# NUC505_v1 register map
File version: 1.0
Registers are 32-bit, read-write, reset 0x0 unless marked. A register's access mark holds for its fields unless they carry their own. Offsets are from the block's base; [hi:lo] are bit positions; {n}, {i} and the like mark numbered series; 'fields as' and 'values as' point back to an identical list.

## USBH — USBH Register Map
Base 0x4000B000
0x00 HCREVISION ro reset 0x110 — Host Controller Revision Register
  [7:0] REV — Revision. Indicates the Open HCI Specification revision number implemented by the Hardware. Host Controller supports 1.1 specification.
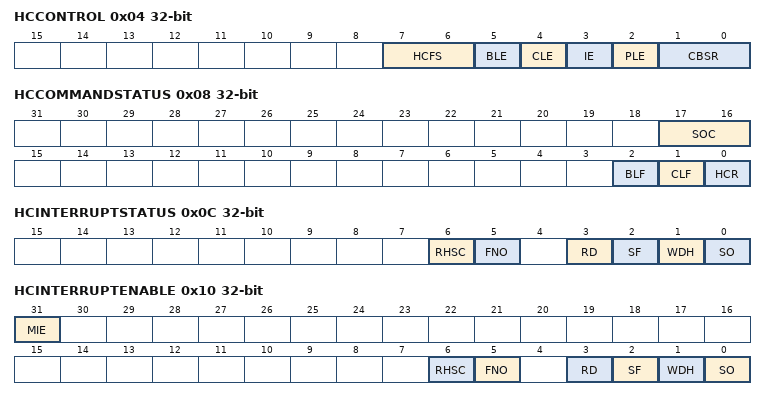
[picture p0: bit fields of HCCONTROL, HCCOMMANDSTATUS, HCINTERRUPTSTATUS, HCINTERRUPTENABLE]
0x04 HCCONTROL — Host Controller Control Register
  [7:6] HCFS — Host Controller Functional State. This field sets the Host Controller state. The Controller may force a state change from USBSUSPEND to USBRESUME after detecting resume signaling from a downstream port. States are:
    0=USBRESET; 1=USBRESUME; 2=USBOPERATIONAL; 3=USBSUSPEND
  [5] BLE — Bulk List Enable Bit
    0=Processing of the Bulk list after next SOF (Start-Of-Frame) Disabled; 1=Processing of the Bulk list in the next frame Enabled
  [4] CLE — Control List Enable Bit
    0=Processing of the Control list after next SOF (Start-Of-Frame) Disabled; 1=Processing of the Control list in the next frame Enabled
  [3] IE — Isochronous Enable Bit. Both ISOEn and PLE (HcControl[2]) high enables Host Controller to process the Isochronous list. Either ISOEn or PLE (HcControl[2]) is low disables Host Controller to process the Isochronous list.
    0=Processing of the Isochronous list after next SOF (Start-Of-Frame) Disabled; 1=Processing of the Isochronous list in the next frame Enabled, if the PLE (HcControl[2]) is high, too
  [2] PLE — Periodic List Enable Bit. When set, this bit enables processing of the Periodic (interrupt and isochronous) list. The Host Controller checks this bit prior to attempting any periodic transfers in a frame. To enable the processing of the Isochronous list, user has to set both PLE and IE (HcControl[3]) high.
    0=Processing of the Periodic (Interrupt and Isochronous) list after next SOF (Start-Of-Frame) Disabled; 1=Processing of the Periodic (Interrupt and Isochronous) list in the next frame Enabled
  [1:0] CBSR — Control Bulk Service Ratio. This specifies the service ratio between Control and Bulk EDs. Before processing any of the non-periodic lists, HC must compare the ratio specified with its internal count on how many nonempty Control EDs have been processed, in determining whether to continue serving another Control ED or switching to Bulk EDs. The internal count will be retained when crossing the frame boundary. In case of reset, HCD is responsible for restoring this. Value.
    {v}=Number of Control EDs over Bulk EDs served is {v+1}:1 (v=0..3)
0x08 HCCOMMANDSTATUS — Host Controller Command Status Register
  [17:16] SOC — Scheduling Overrun Count. These bits are incremented on each scheduling overrun error. It is initialized to 00b and wraps around at 11b. This will be incremented when a scheduling overrun is detected even if SO (HcInterruptStatus[0]) has already been set.
  [2] BLF — Bulk List Filled. Set high to indicate there is an active TD on the Bulk list. This bit may be set by either software or the Host Controller and cleared by the Host Controller each time it begins processing the head of the Bulk list.
    0=No active TD found or Host Controller begins to process the head of the Bulk list; 1=An active TD added or found on the Bulk list
  [1] CLF — Control List Filled. Set high to indicate there is an active TD on the Control List. It may be set by either software or the Host Controller and cleared by the Host Controller each time it begins processing the head of the Control List.
    0=No active TD found or Host Controller begins to process the head of the Control list; 1=An active TD added or found on the Control list
  [0] HCR — Host Controller Reset. This bit is set to initiate the software reset of Host Controller. This bit is cleared by the Host Controller, upon completed of the reset operation. This bit, when set, didn't reset the Root Hub and no subsequent reset signaling be asserted to its downstream ports.
    0=Host Controller is not in software reset state; 1=Host Controller is in software reset state
0x0C HCINTERRUPTSTATUS — Host Controller Interrupt Status Register
  [6] RHSC — Root Hub Status Change. This bit is set when the content of HcRhStatus or the content of HcRhPortStatus1 register has changed.
    0=The content of HcRhStatus and the content of HcRhPortStatus1 register didn't change; 1=The content of HcRhStatus or the content of HcRhPortStatus1 register has changed
  [5] FNO — Frame Number Overflow. This bit is set when bit 15 of Frame Number changes from 1 to 0 or from 0 to 1.
    0=The bit 15 of Frame Number didn't change; 1=The bit 15 of Frame Number changes from 1 to 0 or from 0 to 1
  [3] RD — Resume Detected. Set when Host Controller detects resume signaling on a downstream port.
    0=No resume signaling detected on a downstream port; 1=Resume signaling detected on a downstream port
  [2] SF — Start of Frame. Set when the Frame Management functional block signals a 'Start of Frame' event. Host Control generates a SOF token at the same time.
    0=.Not the start of a frame; 1=.Indicate the start of a frame and Host Controller generates a SOF token
  [1] WDH — Write Back Done Head. Set after the Host Controller has written HcDoneHead to HccaDoneHead. Further updates of the HccaDoneHead will not occur until this bit has been cleared.
    0=.Host Controller didn't update HccaDoneHead; 1=.Host Controller has written HcDoneHead to HccaDoneHead
  [0] SO — Scheduling Overrun. Set when the List Processor determines a Schedule Overrun has occurred.
    0=Schedule Overrun didn't occur; 1=Schedule Overrun has occurred
0x10 HCINTERRUPTENABLE — Host Controller Interrupt Enable Control Register
  [31] MIE — Master Interrupt Enable Bit. This bit is a global interrupt enable. A write of '1' allows interrupts to be enabled via the specific enable bits listed above. Write Operation:
    0=No effect. Interrupt generation due to RHSC (HcInterruptStatus[6]), FNO (HcInterruptStatus[5]), RD (HcInterruptStatus[3]), SF (HcInterruptStatus[2]), WDH (HcInterruptStatus[1]) or SO (HcInterruptStatus[0]) Disabled even if the corresponding bit in HcInterruptEnable is high; 1=Interrupt generation due to RHSC (HcInterruptStatus[6]), FNO (HcInterruptStatus[5]), RD (HcInterruptStatus[3]), SF (HcInterruptStatus[2]), WDH (HcInterruptStatus[1]) or SO (HcInterruptStatus[0]) Enabled if the corresponding bit in HcInterruptEnable is high
  [6] RHSC — Root Hub Status Change Interrupt Enable Bit. Write Operation:
    0=No effect. Interrupt generation due to RHSC (HcInterruptStatus[6]) Disabled; 1=Interrupt generation due to RHSC (HcInterruptStatus[6]) Enabled
  [5] FNO — Frame Number Overflow Interrupt Enable Bit. Write Operation:
    0=No effect. Interrupt generation due to FNO (HcInterruptStatus[5]) Disabled; 1=Interrupt generation due to FNO (HcInterruptStatus[5]) Enabled
  [3] RD — Resume Detected Interrupt Enable Bit. Write Operation:
    0=No effect. Interrupt generation due to RD (HcInterruptStatus[3]) Disabled; 1=Interrupt generation due to RD (HcInterruptStatus[3]) Enabled
  [2] SF — Start of Frame Interrupt Enable Bit. Write Operation:
    0=No effect. Interrupt generation due to SF (HcInterruptStatus[2]) Disabled; 1=Interrupt generation due to SF (HcInterruptStatus[2]) Enabled
  [1] WDH — Write Back Done Head Interrupt Enable Bit. Write Operation:
    0=No effect. Interrupt generation due to WDH (HcInterruptStatus[1]) Disabled; 1=Interrupt generation due to WDH (HcInterruptStatus[1]) Enabled
  [0] SO — Scheduling Overrun Interrupt Enable Bit. Write Operation:
    0=No effect. Interrupt generation due to SO (HcInterruptStatus[0]) Disabled; 1=Interrupt generation due to SO (HcInterruptStatus[0]) Enabled
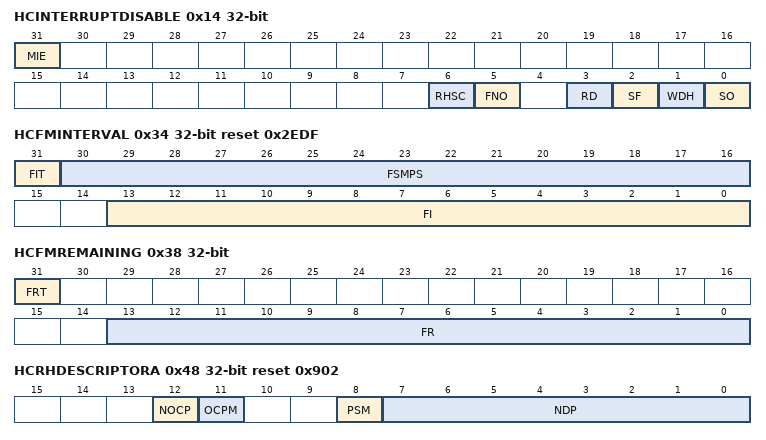
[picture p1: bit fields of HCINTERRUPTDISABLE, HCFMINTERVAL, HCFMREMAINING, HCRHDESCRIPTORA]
0x14 HCINTERRUPTDISABLE — Host Controller Interrupt Disable Control Register
  [31] MIE — Master Interrupt Disable Bit. Global interrupt disable. Writing '1' to disable all interrupts. Write Operation:
    0=No effect. Interrupt generation due to RHSC (HcInterruptStatus[6]), FNO (HcInterruptStatus[5]), RD (HcInterruptStatus[3]), SF (HcInterruptStatus[2]), WDH (HcInterruptStatus[1]) or SO (HcInterruptStatus[0]) Disabled even if the corresponding bit in HcInterruptEnable is high; 1=Interrupt generation due to RHSC (HcInterruptStatus[6]), FNO (HcInterruptStatus[5]), RD (HcInterruptStatus[3]), SF (HcInterruptStatus[2]), WDH (HcInterruptStatus[1]) or SO (HcInterruptStatus[0]) Disabled if the corresponding bit in HcInterruptEnable is high. Interrupt generation due to RHSC (HcInterruptStatus[6]), FNO (HcInterruptStatus[5]), RD (HcInterruptStatus[3]), SF (HcInterruptStatus[2]), WDH (HcInterruptStatus[1]) or SO (HcInterruptStatus[0]) Enabled if the corresponding bit in HcInterruptEnable is high
  [6] RHSC — Root Hub Status Change Disable Bit. Write Operation:
    0=No effect. Interrupt generation due to RHSC (HcInterruptStatus[6]) Disabled; 1=Interrupt generation due to RHSC (HcInterruptStatus[6]) Disabled. Interrupt generation due to RHSC (HcInterruptStatus[6]) Enabled
  [5] FNO — Frame Number Overflow Disable Bit. Write Operation:
    0=No effect. Interrupt generation due to FNO (HcInterruptStatus[5]) Disabled; 1=Interrupt generation due to FNO (HcInterruptStatus[5]) Disabled. Interrupt generation due to FNO (HcInterruptStatus[5]) Enabled
  [3] RD — Resume Detected Disable Bit. Write Operation:
    0=No effect. Interrupt generation due to RD (HcInterruptStatus[3]) Disabled; 1=Interrupt generation due to RD (HcInterruptStatus[3]) Disabled. Interrupt generation due to RD (HcInterruptStatus[3]) Enabled
  [2] SF — Start of Frame Disable Bit. Write Operation:
    0=No effect. Interrupt generation due to SF (HcInterruptStatus[2]) Disabled; 1=Interrupt generation due to SF (HcInterruptStatus[2]) Disabled. Interrupt generation due to SF (HcInterruptStatus[2]) Enabled
  [1] WDH — Write Back Done Head Disable Bit. Write Operation:
    0=No effect. Interrupt generation due to WDH (HcInterruptStatus[1]) Disabled; 1=Interrupt generation due to WDH (HcInterruptStatus[1]) Disabled. Interrupt generation due to WDH (HcInterruptStatus[1]) Enabled
  [0] SO — Scheduling Overrun Disable Bit. Write Operation:
    0=No effect. Interrupt generation due to SO (HcInterruptStatus[0]) Disabled; 1=Interrupt generation due to SO (HcInterruptStatus[0]) Disabled. Interrupt generation due to SO (HcInterruptStatus[0]) Enabled
0x18 HCHCCA — Host Controller Communication Area Register
  [31:8] HCCA — Host Controller Communication Area. Pointer to indicate base address of the Host Controller Communication Area (HCCA).
0x1C HCPERIODCURRENTED — Host Controller Period Current ED Register
  [31:4] PCED — Periodic Current ED. Pointer to indicate physical address of the current Isochronous or Interrupt Endpoint Descriptor.
0x20 HCCONTROLHEADED — Host Controller Control Head ED Register
  [31:4] CHED — Control Head ED. Pointer to indicate physical address of the first Endpoint Descriptor of the Control list.
0x24 HCCONTROLCURRENTED — Host Controller Control Current ED Register
  [31:4] CCED — Control Current Head ED. Pointer to indicate the physical address of the current Endpoint Descriptor of the Control list.
0x28 HCBULKHEADED — Host Controller Bulk Head ED Register
  [31:4] BHED — Bulk Head ED. Pointer to indicate the physical address of the first Endpoint Descriptor of the Bulk list.
0x2C HCBULKCURRENTED — Host Controller Bulk Current ED Register
  [31:4] BCED — Bulk Current Head ED. Pointer to indicate the physical address of the current endpoint of the Bulk list.
0x30 HCDONEHEAD — Host Controller Done Head Register
  [31:4] DH — Done Head. Pointer to indicate the physical address of the last completed Transfer Descriptor that was added to the Done queue.
0x34 HCFMINTERVAL reset 0x2EDF — Host Controller Frame Interval Register
  [31] FIT — Frame Interval Toggle. This bit is toggled by Host Controller Driver when it loads a new value into FI (HcFmInterval[13:0]).
    0=Host Controller Driver didn't load new value into FI (HcFmInterval[13:0]); 1=Host Controller Driver loads a new value into FI (HcFmInterval[13:0])
  [30:16] FSMPS — FS Largest Data Packet. This field specifies a value that is loaded into the Largest Data Packet Counter at the beginning of each frame.
  [13:0] FI — Frame Interval. This field specifies the length of a frame as (bit times - 1). For 12,000 bit times in a frame, a value of 11,999 is stored here.
0x38 HCFMREMAINING ro — Host Controller Frame Remaining Register
  [31] FRT — Frame Remaining Toggle. This bit is loaded from the FIT (HcFmInterval[31]) whenever FR (HcFmRemaining[13:0]) reaches 0.
  [13:0] FR — Frame Remaining. When the Host Controller is in the USBOPERATIONAL state, this 14-bit field decrements each 12 MHz clock period. When the count reaches 0, (end of frame) the counter reloads with Frame Interval. In addition, the counter loads when the Host Controller transitions into USBOPERATIONAL.
0x3C HCFMNUMBER ro — Host Controller Frame Number Register
  [15:0] FN — Frame Number. This 16-bit incrementing counter field is incremented coincident with the loading of FR (HcFmRemaining[13:0]). The count rolls over from 'FFFFh' to '0h.'
0x40 HCPERIODICSTART — Host Controller Periodic Start Register
  [13:0] PS — Periodic Start. This field contains a value used by the List Processor to determine where in a frame the Periodic List processing must begin.
0x44 HCLSTHRESHOLD reset 0x628 — Host Controller Low-speed Threshold Register
  [11:0] LST — Low-speed Threshold
0x48 HCRHDESCRIPTORA reset 0x902 — Host Controller Root Hub Descriptor A Register
  [12] NOCP — No Overcurrent Protection. This bit describes how the overcurrent status for the Root Hub ports reported.
    0=Overcurrent status is reported; 1=Overcurrent status is not reported
  [11] OCPM — Overcurrent Protection Mode. This bit describes how the overcurrent status for the Root Hub ports reported. This bit is only valid when NOCP (HcRhDescriptorA[12]) is cleared.
    0=Global Overcurrent; 1=Individual Overcurrent
  [8] PSM — Power Switching Mode. This bit is used to specify how the power switching of the Root Hub ports is controlled.
    0=Global Switching; 1=Individual Switching
  [7:0] NDP — Number Downstream Ports. Root Hub supports two downstream ports. It's 2 in this Root Hub.
0x4C HCRHDESCRIPTORB — Host Controller Root Hub Descriptor B Register
  [31:16] PPCM — Port Power Control Mask. Global power switching. This field is only valid if PowerSwitchingMode is set (individual port switching). When set, the port only responds to individual port power switching commands (Set/ClearPortPower). When cleared, the port only responds to global power switching commands (Set/ClearGlobalPower). PPCM[15:3] and PPCM[0] are reserved.
    0=Port power controlled by global power switching; 1=Port power controlled by port power switching
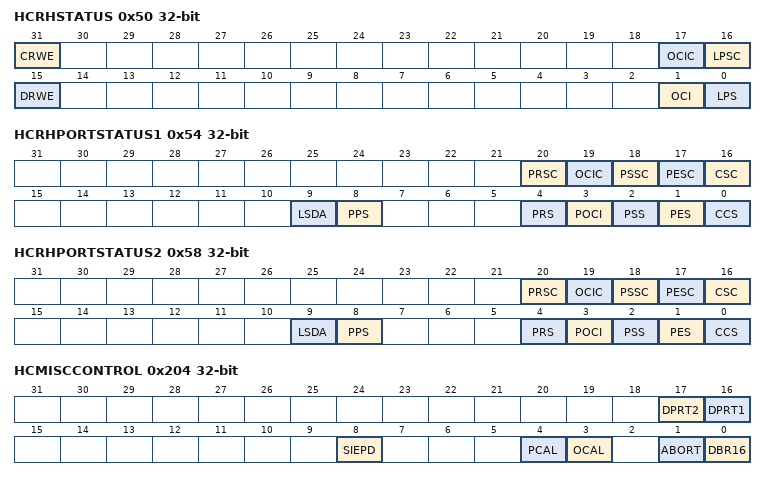
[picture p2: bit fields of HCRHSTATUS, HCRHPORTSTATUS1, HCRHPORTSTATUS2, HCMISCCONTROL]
0x50 HCRHSTATUS — Host Controller Root Hub Status Register
  [31] CRWE — Clear Remote Wake-up Enable Bit. This bit is used to clear DRWE (HcRhStatus[15]). This bit is always read as zero. Write Operation:
    0=No effect; 1=Clear DRWE (HcRhStatus[15])
  [17] OCIC — Overcurrent Indicator Change. This bit is set by hardware when a change has occurred in OCI (HcRhStatus[1]). Write 1 to clear this bit to zero.
    0=OCI (HcRhStatus[1]) is not changed; 1=OCI (HcRhStatus[1]) is changed
  [16] LPSC — Set Global Power
    0=No effect; 1=Set global power
  [15] DRWE — Device Remote Wake-up Enable Bit. This bit controls if port's Connect Status Change as a remote wake-up event. Write Operation:
    0=No effect. Connect status changed as a remote wake-up event Disabled; 1=Connect status changed as a remote wake-up event Enabled
  [1] OCI — Overcurrent Indicator. This bit reflects the state of the overcurrent status pin. This field is only valid if NOCP (HcRhDesA[12]) and OCPM (HcRhDesA[11]) are cleared.
    0=No overcurrent condition; 1=Overcurrent condition
  [0] LPS — Clear Global Power
    0=No effect; 1=Clear global power
0x54 HCRHPORTSTATUS1 — Host Controller Root Hub Port Status [1]
  [20] PRSC — Port Reset Status Change. This bit indicates that the port reset signal has completed. Write 1 to clear this bit to zero.
    0=Port reset is not completed; 1=Port reset is completed
  [19] OCIC — Port Overcurrent Indicator Change. This bit is set when POCI (HcRhPortStatus1[3]) changes. Write 1 to clear this bit to zero.
    0=POCI (HcRhPortStatus1[3]) is not changed; 1=POCI (HcRhPortStatus1[3]) is changed
  [18] PSSC — Port Suspend Status Change. This bit indicates the completion of the selective resume sequence for the port. Write 1 to clear this bit to zero.
    0=Port resume is not completed; 1=Port resume is completed
  [17] PESC — Port Enable Status Change. This bit indicates that the port has been disabled (PES (HcRhPortStatus1[1]) cleared) due to a hardware event. Write 1 to clear this bit to zero.
    0=PES (HcRhPortStatus1[1]) is not changed; 1=PES (HcRhPortStatus1[1]) is changed
  [16] CSC — Connect Status Change. This bit indicates connect or disconnect event has been detected (CCS (HcRhPortStatus1[0]) changed). Write 1 to clear this bit to zero.
    0=No connect/disconnect event (CCS (HcRhPortStatus1[0]) didn't change); 1=Hardware detection of connect/disconnect event (CCS (HcRhPortStatus1[0]) changed)
  [9] LSDA — Low Speed Device Attached (Read) or Clear Port Power (Write). This bit defines the speed (and bud idle) of the attached device. It is only valid when CCS (HcRhPortStatus1[0]) is set. This bit is also used to clear port power. Write Operation:
    0=No effect. Full Speed device; 1=Clear PPS (HcRhPortStatus1[8]). Low-speed device
  [8] PPS — Port Power Status. This bit reflects the power state of the port regardless of the power switching mode. Write Operation:
    0=No effect. Port power Diabled; 1=Port Power Enabled. Port power Enabled
  [4] PRS — Port Reset Status. This bit reflects the reset state of the port. Write Operation:
    0=No effect. Port reset signal is not active; 1=Set port reset. Port reset signal is active
  [3] POCI — Port Overcurrent Indicator (Read) or Clear Port Suspend (Write). This bit reflects the state of the overcurrent status pin dedicated to this port. This field is only valid if NOCP (HcRhDescriptorA[12]) is cleared and OCPM (HcRhDescriptorA[11]) is set. This bit is also used to initiate the selective result sequence for the port. Write Operation:
    0=No effect. No overcurrent condition; 1=Clear port suspend. Overcurrent condition
  [2] PSS — Port Suspend Status. This bit indicates the port is suspended. Write Operation:
    0=No effect. Port is not suspended; 1=Set port suspend. Port is selectively suspended
  [1] PES — Port Enable Status. Write Operation:
    0=No effect. Port Disabled; 1=Set port Enabled. Port Enabled
  [0] CCS — Current Connect Status (Read) or Clear Port Enable Bit (Write). Write Operation:
    0=No effect. No device connected; 1=Clear port Enabled. Device connected
0x58 HCRHPORTSTATUS2 — Host Controller Root Hub Port Status [2]
  fields as HCRHPORTSTATUS1
0x200 HCPHYCONTROL — Host Controller PHY Control Register
  [27] STBYEN — USB Transceiver Standby Enable Bit. This bit controls if USB transceiver could enter the standby mode to reduce power consumption.
    0=The USB transceiver would never enter the standby mode; 1=The USB transceiver will enter Standby mode while port is in power off state (port power is inactive)
0x204 HCMISCCONTROL — Host Controller Miscellaneous Control Register
  [17] DPRT2 — Port 2 Disable Bit. This bit controls if the connection between USB host controller and transceiver of port 2 is disabled. If the connection is disabled, the USB host controller will not recognize any event of USB bus. Set this bit high, the transceiver of port 2 will also be forced into the standby mode no matter what USB host controller operation is.
    0=The connection between USB host controller and transceiver of port 2 is enabled; 1=The connection between USB host controller and transceiver of port 2 is disabled and the transceiver of port 2 will also be forced into the standby mode
  [16] DPRT1 — Port 1 Disable Bit. This bit controls if the connection between USB host controller and transceiver of port 1 is disabled. If the connection is disabled, the USB host controller will not recognize any event of USB bus. Set this bit high, the transceiver of port 1 will also be forced into the standby mode no matter what USB host controller operation is.
    0=The connection between USB host controller and transceiver of port 1 is enabled; 1=The connection between USB host controller and transceiver of port 1 is disabled and the transceiver of port 1 will also be forced into the standby mode
  [8] SIEPD — SIE Pipeline Disable Bit. When set, waits for all USB bus activity to complete prior to returning completion status to the List Processor. This is a failsafe mechanism to avoid potential problems with the clk_dr transition between 1.5 MHz and 12 MHz.
  [4] PCAL — Port Power Control Active Low. This bit controls the polarity of port power control to external power IC.
    0=Port power control is high active; 1=Port power control is low active
  [3] OCAL — Overcurrent Active Low. This bit controls the polarity of overcurrent flag from external power IC.
    0=Overcurrent flag is high active; 1=Overcurrent flag is low active
  [1] ABORT — AHB Bus ERROR Response. This bit indicates there is an ERROR response received in AHB bus.
    0=No ERROR response received; 1=ERROR response received
  [0] DBR16 — Data Buffer Region 16. When set, the size of the data buffer region is 16 bytes. Otherwise, the size is 32 bytes.
